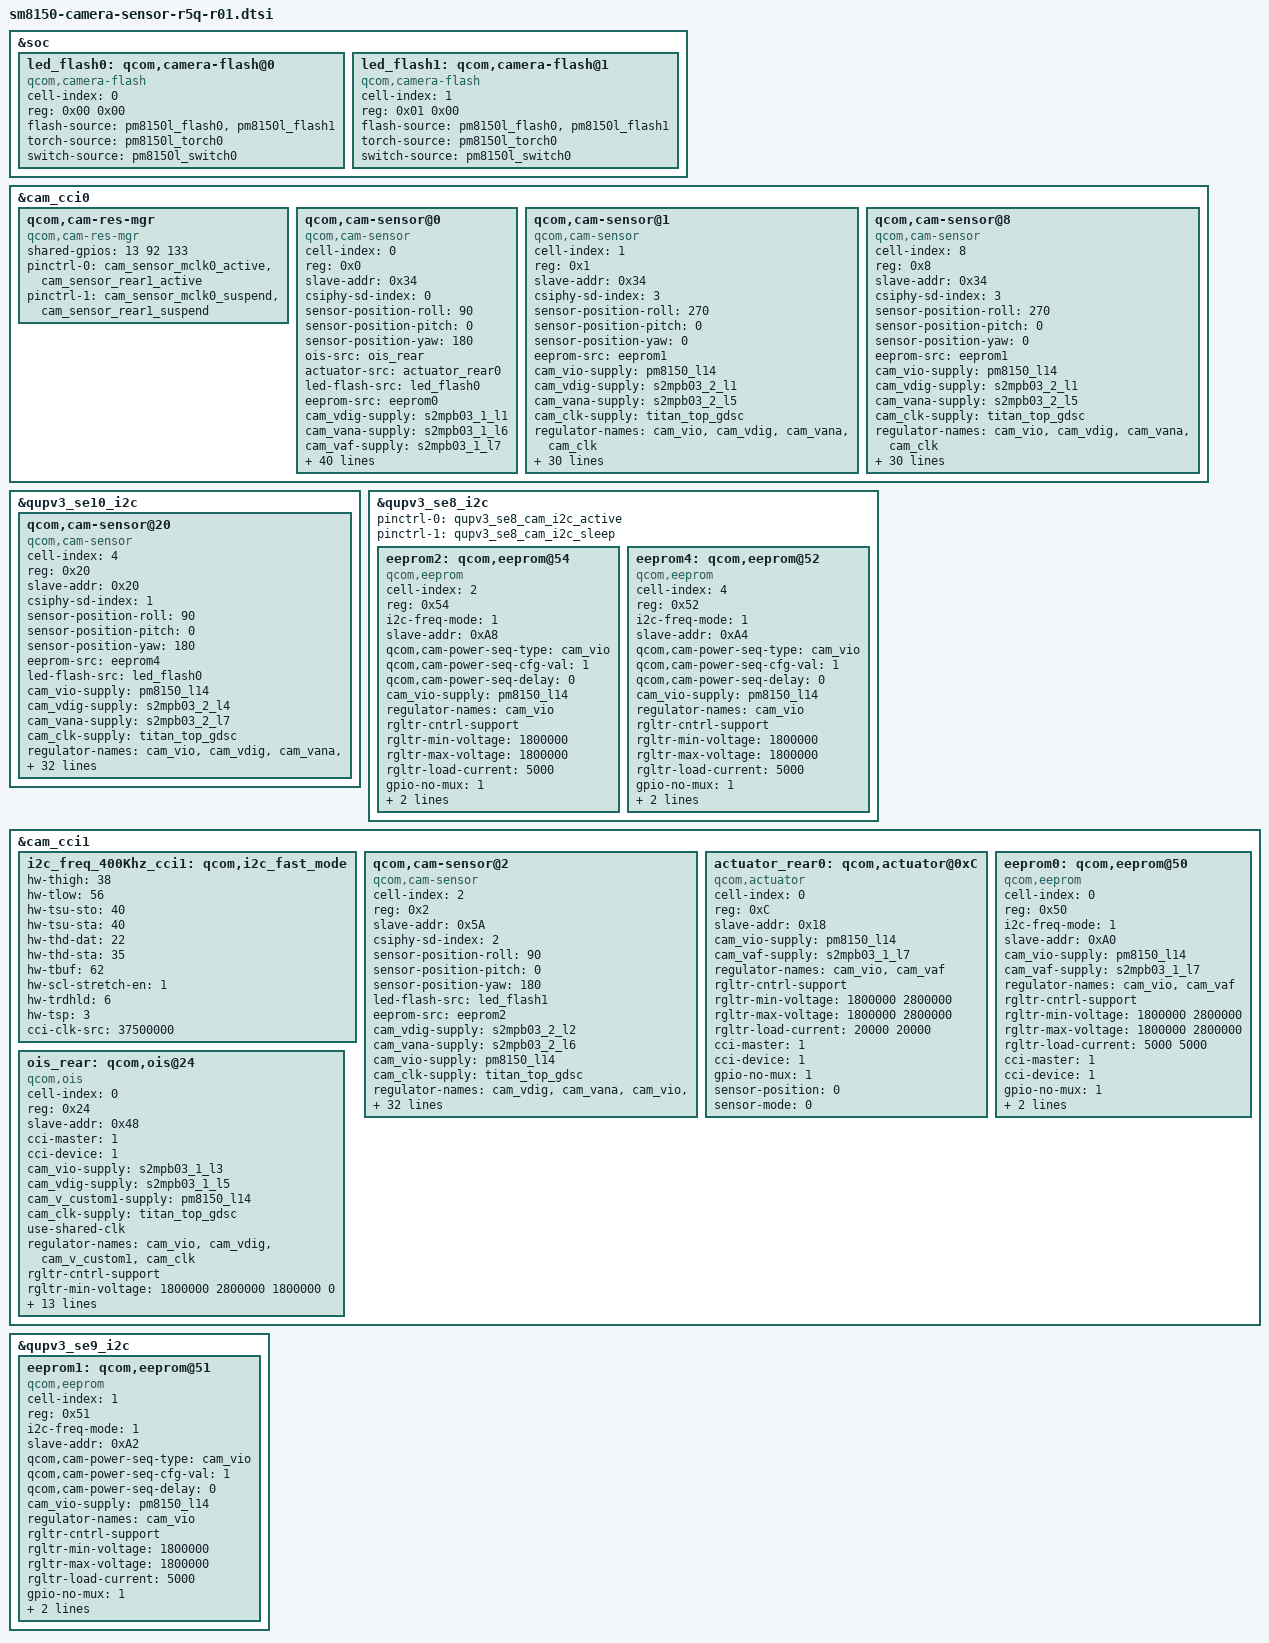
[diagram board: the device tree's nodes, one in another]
&soc {
    led_flash0: qcom,camera-flash@0 {
                cell-index = <0>;
                reg = <0x00 0x00>;
                compatible = "qcom,camera-flash";
                flash-source = <&pm8150l_flash0 &pm8150l_flash1>;
                torch-source = <&pm8150l_torch0>;
                switch-source = <&pm8150l_switch0>;        
                status = "ok";
    };
    
    led_flash1: qcom,camera-flash@1 {
                cell-index = <1>;
                reg = <0x01 0x00>;
                compatible = "qcom,camera-flash";
                flash-source = <&pm8150l_flash0 &pm8150l_flash1>;
                torch-source = <&pm8150l_torch0>;
                switch-source = <&pm8150l_switch0>;        
                status = "ok";
    };
};

&cam_cci0 {

    qcom,cam-res-mgr {
                compatible = "qcom,cam-res-mgr";
                shared-gpios = <13 92 133>;
                pinctrl-names = "cam_res_mgr_default", "cam_res_mgr_suspend";
                status = "ok";
                pinctrl-0 = <&cam_sensor_mclk0_active &cam_sensor_rear1_active>;
                pinctrl-1 = <&cam_sensor_mclk0_suspend &cam_sensor_rear1_suspend>;
    };

    qcom,cam-sensor@0 {
		cell-index = <0>;
		compatible = "qcom,cam-sensor";
		reg = <0x0>;
		slave-addr = <0x34>;
		csiphy-sd-index = <0>;
		sensor-position-roll = <90>;
		sensor-position-pitch = <0>;
		sensor-position-yaw = <180>;
		ois-src = <&ois_rear>;
		actuator-src = <&actuator_rear0>;
		led-flash-src = <&led_flash0>; 
		eeprom-src = <&eeprom0>; 

		// Regulators		
		cam_vdig-supply = <&s2mpb03_1_l1>;        // digital 1.1 S2MPB03X01-6030 VLDO 1 VDD_RCAM1_DVDD_1P1
		cam_vana-supply = <&s2mpb03_1_l6>;        // analog 2.9  S2MPB03X01-6030 VLOD7 VDD_RCAM1_AVDD_2.9V
		cam_vaf-supply = <&s2mpb03_1_l7>;         // S2MPB03X01-6030 LDO6  VDD_RCAM1_AF_2P8
		cam_vio-supply = <&pm8150_l14>;           // VIO 1.8
		cam_v_custom1-supply = <&s2mpb03_2_l3>;   // S2MPB03X01-6031 LDO3  VDD_RCAM1_AVDD_1P8
		cam_v_custom2-supply = <&s2mpb03_1_l3>;	  // S2MPB03X01-6030 LDO3  VDD_RCAM1_OIS_1P8
		cam_v_custom3-supply = <&s2mpb03_1_l5>;   // S2MPB03X01-6030 LDO6  VDD_RCAM1_OIS_VM_2P8
		cam_clk-supply = <&titan_top_gdsc>;                             
		
		
		regulator-names = "cam_vdig", "cam_vana","cam_vaf","cam_vio","cam_v_custom1","cam_v_custom2","cam_v_custom3","cam_clk";
		rgltr-cntrl-support;
		rgltr-min-voltage = <1100000 2900000 2800000 1800000 1800000 1800000 2800000 0 >;
		rgltr-max-voltage = <1100000 2900000 2800000 1800000 1800000 1800000 2800000 0 >;
		rgltr-load-current = <200000 200000 200000 200000 20000 200000 20000 0>;

		// GPIO
		gpio-no-mux = <0>;
		gpios = <&tlmm 13 0>,
			<&tlmm 92 0>,
			<&tlmm 133 0>;  // GPIO 133 for OIS  VDD_RCAM1_OIS_2P8
		gpio-reset = <1>;
		gpio-custom1 = <2>;
		gpio-req-tbl-num = <0 1 2>;
		gpio-req-tbl-flags = <1 0 0>;
		gpio-req-tbl-label = "CAMIF_MCLK0","CAM_RESET0","RCAM1_OIS";

		sensor-mode = <0>;
		cci-master = <0>;
		status = "ok";
		use-shared-clk;
		clocks = <&clock_camcc CAM_CC_MCLK0_CLK>;
		clock-names = "cam_clk";
		clock-cntl-level = "turbo";
		clock-rates = <24000000>;
		cam,isp = <0>;                  // 0 : INT , 1 : EXT , 2 : SOC
		cam,cal_memory = <2>;           // 0 : N , 1 : FROM , 2 : EEPROM , 3 : OTP
		cam,read_version = <0>;         // 0 : SYSFS , 1 : CAMON
		cam,core_voltage = <0>;         // 0 : N , 1 : Y
		cam,upgrade = <0>;              // 0 : N , 1 : SYSFS , 2 : CAMON
		cam,fw_write = <0>;             // 0 : N , 1 : OS , 2 : SD , 3 : ALL
		cam,fw_dump = <0>;              // 0 : N , 1 : Y
		cam,companion_chip = <0>;       // 0 : N , 1 : Y
		cam,ois = <1>;                  // 0 : N , 1 : Y
		cam,dual_open = <0>;            // 0 : N , 1 : Y
		cam,valid = <1>;                // 0 : N , 1 : Y
	};

    qcom,cam-sensor@1 {
		cell-index = <1>;
		compatible = "qcom,cam-sensor";
		reg = <0x1>;
		slave-addr = <0x34>;
		csiphy-sd-index = <3>;
		sensor-position-roll = <270>;
		sensor-position-pitch = <0>;
		sensor-position-yaw = <0>;
		eeprom-src = <&eeprom1>;
		cam_vio-supply = <&pm8150_l14>;
		cam_vdig-supply = <&s2mpb03_2_l1>;
		cam_vana-supply = <&s2mpb03_2_l5>;
		cam_clk-supply = <&titan_top_gdsc>;
		regulator-names = "cam_vio", "cam_vdig", "cam_vana", "cam_clk";
		rgltr-cntrl-support;
		rgltr-min-voltage = <1800000 1050000 2900000 0>;
		rgltr-max-voltage = <1800000 1050000 2900000 0>;
		rgltr-load-current = <200000 200000 200000 0>;
		gpio-no-mux = <0>;
		pinctrl-names = "cam_default", "cam_suspend";
		pinctrl-0 = <&cam_sensor_mclk2_active &cam_sensor_active_front>;
		pinctrl-1 = <&cam_sensor_mclk2_suspend &cam_sensor_suspend_front>;
		gpios = <&tlmm 15 0>, /*VTCAM_MCLK*/
			<&tlmm 82 0>; /*VTCAM_RST*/
		gpio-reset = <1>;
		gpio-req-tbl-num = <0 1>;
		gpio-req-tbl-flags = <1 0>;
		gpio-req-tbl-label = "CAMIF_MCLK2", "CAM_RESET2";

		sensor-mode = <0>;
		cci-master = <1>;
		status = "ok";
		clocks = <&clock_camcc CAM_CC_MCLK2_CLK>;
		clock-names = "cam_clk";
		clock-cntl-level = "turbo";
		clock-rates = <24000000>;

		cam,isp = <0>;                  // 0 : INT , 1 : EXT , 2 : SOC
		cam,cal_memory = <2>;           // 0 : N , 1 : FROM , 2 : EEPROM , 3 : OTP
		cam,read_version = <0>;         // 0 : SYSFS , 1 : CAMON
		cam,core_voltage = <0>;         // 0 : N , 1 : Y
		cam,upgrade = <0>;              // 0 : N , 1 : SYSFS , 2 : CAMON
		cam,fw_write = <0>;             // 0 : N , 1 : OS , 2 : SD , 3 : ALL
		cam,fw_dump = <0>;              // 0 : N , 1 : Y
		cam,companion_chip = <0>;       // 0 : N , 1 : Y
		cam,ois = <0>;                  // 0 : N , 1 : Y
		cam,dual_open = <0>;            // 0 : N , 1 : Y
		cam,valid = <1>;                // 0 : N , 1 : Y
    };	

    qcom,cam-sensor@8 {
		cell-index = <8>;
		compatible = "qcom,cam-sensor";
		reg = <0x8>;
		slave-addr = <0x34>;
		csiphy-sd-index = <3>;
		sensor-position-roll = <270>;
		sensor-position-pitch = <0>;
		sensor-position-yaw = <0>;
		eeprom-src = <&eeprom1>;
		cam_vio-supply = <&pm8150_l14>;
		cam_vdig-supply = <&s2mpb03_2_l1>;
		cam_vana-supply = <&s2mpb03_2_l5>;
		cam_clk-supply = <&titan_top_gdsc>;
		regulator-names = "cam_vio", "cam_vdig", "cam_vana", "cam_clk";
		rgltr-cntrl-support;
		rgltr-min-voltage = <1800000 1050000 2900000 0>;
		rgltr-max-voltage = <1800000 1050000 2900000 0>;
		rgltr-load-current = <200000 200000 200000 0>;
		gpio-no-mux = <0>;
		pinctrl-names = "cam_default", "cam_suspend";
		pinctrl-0 = <&cam_sensor_mclk2_active &cam_sensor_active_front>;
		pinctrl-1 = <&cam_sensor_mclk2_suspend &cam_sensor_suspend_front>;
		gpios = <&tlmm 15 0>, /*VTCAM_MCLK*/
			<&tlmm 82 0>; /*VTCAM_RST*/
		gpio-reset = <1>;
		gpio-req-tbl-num = <0 1>;
		gpio-req-tbl-flags = <1 0>;
		gpio-req-tbl-label = "CAMIF_MCLK2", "CAM_RESET2";

		sensor-mode = <0>;
		cci-master = <1>;
		status = "ok";
		clocks = <&clock_camcc CAM_CC_MCLK2_CLK>;
		clock-names = "cam_clk";
		clock-cntl-level = "turbo";
		clock-rates = <24000000>;

		cam,isp = <0>;                  // 0 : INT , 1 : EXT , 2 : SOC
		cam,cal_memory = <2>;           // 0 : N , 1 : FROM , 2 : EEPROM , 3 : OTP
		cam,read_version = <0>;         // 0 : SYSFS , 1 : CAMON
		cam,core_voltage = <0>;         // 0 : N , 1 : Y
		cam,upgrade = <0>;              // 0 : N , 1 : SYSFS , 2 : CAMON
		cam,fw_write = <0>;             // 0 : N , 1 : OS , 2 : SD , 3 : ALL
		cam,fw_dump = <0>;              // 0 : N , 1 : Y
		cam,companion_chip = <0>;       // 0 : N , 1 : Y
		cam,ois = <0>;                  // 0 : N , 1 : Y
		cam,dual_open = <0>;            // 0 : N , 1 : Y
		cam,valid = <1>;                // 0 : N , 1 : Y
	};
};

&qupv3_se10_i2c {
    status = "ok";
	
	qcom,cam-sensor@20 {  /* REAR CAM 3 - 5M */
		cell-index = <4>;
		compatible = "qcom,cam-sensor";
		reg = <0x20>;
		slave-addr = <0x20>;
		csiphy-sd-index = <1>;
		sensor-position-roll = <90>;
		sensor-position-pitch = <0>;
		sensor-position-yaw = <180>;
                eeprom-src = <&eeprom4>;
                led-flash-src = <&led_flash0>;


		// LDO
		cam_vio-supply = <&pm8150_l14>;
		cam_vdig-supply = <&s2mpb03_2_l4>; 
		cam_vana-supply = <&s2mpb03_2_l7>;
		cam_clk-supply = <&titan_top_gdsc>;
		regulator-names = "cam_vio", "cam_vdig", "cam_vana", "cam_clk";
		rgltr-cntrl-support;
		rgltr-min-voltage = <1800000 1200000 2800000 0>;
		rgltr-max-voltage = <1800000 1200000 2800000 0>;
		rgltr-load-current = <200000 200000 200000 0>;

		// GPIO
		gpio-no-mux = <0>;
		pinctrl-names = "cam_default", "cam_suspend";
		pinctrl-0 = <&cam_sensor_mclk3_active &cam_sensor_active_sw>;
		pinctrl-1 = <&cam_sensor_mclk3_suspend &cam_sensor_suspend_sw>;

		gpios = <&tlmm 16 0>,
			<&tlmm 21 0>;

		gpio-reset = <1>;
		gpio-req-tbl-num = <0 1>;
		gpio-req-tbl-flags = <1 0>;
		gpio-req-tbl-label = "CAMIF_MCLK3", "CAM_RESET3";

		sensor-mode = <0>;
		cci-device = <0>;
		cci-master = <1>;
		status = "ok";
		clocks = <&clock_camcc CAM_CC_MCLK3_CLK>;
		clock-names = "cam_clk";
		clock-cntl-level = "turbo";
		clock-rates = <19200000>;

		cam,isp = <0>;                  // 0 : INT , 1 : EXT , 2 : SOC
		cam,cal_memory = <0>;           // 0 : N , 1 : FROM , 2 : EEPROM , 3 : OTP
		cam,read_version = <0>;         // 0 : SYSFS , 1 : CAMON
		cam,core_voltage = <0>;         // 0 : N , 1 : Y
		cam,upgrade = <0>;              // 0 : N , 1 : SYSFS , 2 : CAMON
		cam,fw_write = <0>;             // 0 : N , 1 : OS , 2 : SD , 3 : ALL
		cam,fw_dump = <0>;              // 0 : N , 1 : Y
		cam,companion_chip = <0>;       // 0 : N , 1 : Y
		cam,ois = <0>;                  // 0 : N , 1 : Y
		cam,dual_open = <0>;            // 0 : N , 1 : Y
		cam,valid = <1>;                // 0 : N , 1 : Y
	};
};

&qupv3_se8_i2c{
	pinctrl-0 = <&qupv3_se8_cam_i2c_active>;
	pinctrl-1 = <&qupv3_se8_cam_i2c_sleep>;
	status = "ok";
	eeprom2: qcom,eeprom@54 {
		cell-index = <2>;
		reg = <0x54>;
		compatible = "qcom,eeprom";
		i2c-freq-mode = <1>;
		slave-addr = <0xA8>;

		//cci-master = <0>;
		//cci-device = <1>;
		qcom,cam-power-seq-type = "cam_vio";
		qcom,cam-power-seq-cfg-val = <1>;
		qcom,cam-power-seq-delay = <0>;
		cam_vio-supply = <&pm8150_l14>; /* VDD_MAINCAM_IO_1P8 */
		regulator-names = "cam_vio";
		rgltr-cntrl-support;
		rgltr-min-voltage = <1800000>;
		rgltr-max-voltage = <1800000>;
		rgltr-load-current = <5000>;
		
		gpio-no-mux = <1>;
		sensor-position = <0>;
		sensor-mode = <0>;
		status = "ok";
	};            

	eeprom4: qcom,eeprom@52 {
		cell-index = <4>;
		reg = <0x52>;
		compatible = "qcom,eeprom";
		i2c-freq-mode = <1>;
		slave-addr = <0xA4>;

		//cci-master = <0>;
		//cci-device = <1>;
		qcom,cam-power-seq-type = "cam_vio";
		qcom,cam-power-seq-cfg-val = <1>;
		qcom,cam-power-seq-delay = <0>;
		cam_vio-supply = <&pm8150_l14>; /* VDD_MAINCAM_IO_1P8 */
		regulator-names = "cam_vio";
		rgltr-cntrl-support;
		rgltr-min-voltage = <1800000>;
		rgltr-max-voltage = <1800000>;
		rgltr-load-current = <5000>;
		
		gpio-no-mux = <1>;
		sensor-position = <0>;
		sensor-mode = <0>;
		status = "ok";
	};
};

&cam_cci1 {

        /* This node is added to enable the "I2C Clock Stretching" for tOIS module */
        i2c_freq_400Khz_cci1: qcom,i2c_fast_mode {
                        hw-thigh = <38>;
                        hw-tlow = <56>;
                        hw-tsu-sto = <40>;
                        hw-tsu-sta = <40>;
                        hw-thd-dat = <22>;
                        hw-thd-sta = <35>;
                        hw-tbuf = <62>;
                        hw-scl-stretch-en = <1>;
                        hw-trdhld = <6>;
                        hw-tsp = <3>;
                        cci-clk-src = <37500000>;
                        status = "ok";
        };

	qcom,cam-sensor@2 {
		cell-index = <2>;
		compatible = "qcom,cam-sensor";
		reg = <0x2>;
		slave-addr = <0x5A>; 
		csiphy-sd-index = <2>;
		sensor-position-roll = <90>;
		sensor-position-pitch = <0>;
		sensor-position-yaw = <180>;
		/*actuator-src = <&actuator_rear0>;*/
		led-flash-src = <&led_flash1>; 
		eeprom-src = <&eeprom2>; 

		// Regulators	
		cam_vdig-supply = <&s2mpb03_2_l2>;        // analog 1.05  S2MPB03X01-6030 VLOD2 VDD_RCAM3_DVDD_1P05V        
		cam_vana-supply = <&s2mpb03_2_l6>;        // digital 2.8 S2MPB03X01-6030 VLDO6 VDD_RCAM3_AVDD_2P8V
	        cam_vio-supply = <&pm8150_l14>;         // PMIC vio	
		cam_clk-supply = <&titan_top_gdsc>;                 
		
		
		regulator-names = "cam_vdig", "cam_vana","cam_vio","cam_clk";
		rgltr-cntrl-support;
		rgltr-min-voltage = <1050000 2800000 1800000 0 >;
		rgltr-max-voltage = <1050000 2800000 1800000 0 >;
		rgltr-load-current = <200000 200000 200000 0>;

		// GPIO
		gpio-no-mux = <0>;
		pinctrl-names = "cam_default", "cam_suspend";
		pinctrl-0 = <&cam_sensor_mclk1_active &cam_sensor_rear2_active>;
		pinctrl-1 = <&cam_sensor_mclk1_suspend &cam_sensor_rear2_suspend>;
		gpios = <&tlmm 14 0>,//UWCAM_MCLK
			<&tlmm 22 0>; //UWCAM_RST_N  
		gpio-reset = <1>;
		gpio-req-tbl-num = <0 1>;
		gpio-req-tbl-flags = <1 0>;
		gpio-req-tbl-label = "CAMIF_MCLK1","CAM_RESET1"; 

		sensor-mode = <0>;
		cci-master = <0>;
		cci-device = <1>;
		status = "ok";
		clocks = <&clock_camcc CAM_CC_MCLK1_CLK>;
		clock-names = "cam_clk";
		clock-cntl-level = "turbo";
		clock-rates = <19200000>;
		cam,isp = <0>;                  // 0 : INT , 1 : EXT , 2 : SOC
		cam,cal_memory = <2>;           // 0 : N , 1 : FROM , 2 : EEPROM , 3 : OTP
		cam,read_version = <0>;         // 0 : SYSFS , 1 : CAMON
		cam,core_voltage = <0>;         // 0 : N , 1 : Y
		cam,upgrade = <0>;              // 0 : N , 1 : SYSFS , 2 : CAMON
		cam,fw_write = <0>;             // 0 : N , 1 : OS , 2 : SD , 3 : ALL
		cam,fw_dump = <0>;              // 0 : N , 1 : Y
		cam,companion_chip = <0>;       // 0 : N , 1 : Y
		cam,ois = <0>;                  // 0 : N , 1 : Y
		cam,dual_open = <0>;            // 0 : N , 1 : Y
		cam,valid = <1>;                // 0 : N , 1 : Y
	};
	
	actuator_rear0: qcom,actuator@0xC {
		cell-index = <0>;
		reg = <0xC>;
		compatible = "qcom,actuator";
		slave-addr = <0x18>;


		cam_vio-supply = <&pm8150_l14>;
		cam_vaf-supply = <&s2mpb03_1_l7>;

                regulator-names = "cam_vio","cam_vaf";
		rgltr-cntrl-support;
		rgltr-min-voltage = <1800000 2800000>;
		rgltr-max-voltage = <1800000 2800000>;
		rgltr-load-current = <20000 20000>;

		cci-master = <1>;
		cci-device = <1>;   

		gpio-no-mux = <1>;
		sensor-position = <0>;
		sensor-mode = <0>;
		status = "ok";
	};       
	eeprom0: qcom,eeprom@50 {
		cell-index = <0>;
		reg = <0x50>;
		compatible = "qcom,eeprom";
		i2c-freq-mode = <1>;
		slave-addr = <0xA0>;
                
		cam_vio-supply = <&pm8150_l14>; /* VDD_MAINCAM_IO_1P8 */ 
		cam_vaf-supply = <&s2mpb03_1_l7>;
        
		regulator-names = "cam_vio","cam_vaf";
		rgltr-cntrl-support;
		rgltr-min-voltage = <1800000 2800000>;
		rgltr-max-voltage = <1800000 2800000>;
		rgltr-load-current = <5000 5000>;
		
		cci-master = <1>;
		cci-device = <1>;     
		
		gpio-no-mux = <1>;
		sensor-position = <0>;
		sensor-mode = <0>;
		status = "ok";
	};

	ois_rear: qcom,ois@24  {   /* IMX586 RUMBA_S4 tOIS module */
		compatible = "qcom,ois";
		cell-index = <0>;
		reg = <0x24>;
                slave-addr = <0x48>;
		cci-master = <1>;
		cci-device = <1>;
		cam_vio-supply = <&s2mpb03_1_l3>;	// S2MPB03X01-6030 LDO3 VDD_RCAM1_OIS_1P8
                cam_vdig-supply = <&s2mpb03_1_l5>;      // S2MPB03X01-6030 LDO6 VDD_RCAM1_OIS_VM_2P8
		cam_v_custom1-supply = <&pm8150_l14>;   // VIO supply
                cam_clk-supply = <&titan_top_gdsc>;
                use-shared-clk;

		regulator-names = "cam_vio", "cam_vdig","cam_v_custom1","cam_clk";
		rgltr-cntrl-support;
		rgltr-min-voltage = <1800000 2800000 1800000 0>;
		rgltr-max-voltage = <1800000 2800000 1800000 0>;
		rgltr-load-current = <5000 5000 5000 0>;
		gpio-no-mux = <0>;

                gpios = <&tlmm 13 0>,
			<&tlmm 92 0>,
                        <&tlmm 133 0>;  // GPIO 133 for OIS  VDD_RCAM1_OIS_2P8
                gpio-reset = <1>;
                gpio-custom1 = <2>;
                gpio-req-tbl-num = <0 1 2>;
                gpio-req-tbl-flags = <1 0 0>;
                gpio-req-tbl-label = "CAMIF_MCLK0","CAM_RESET0","RCAM1_OIS";

                clocks = <&clock_camcc CAM_CC_MCLK0_CLK>;
                clock-names = "cam_clk";
                clock-cntl-level = "turbo";
                clock-rates = <24000000>;
	
		status = "ok";
	};	
};

&qupv3_se9_i2c{
        status = "ok";
        eeprom1: qcom,eeprom@51 {
                cell-index = <1>;
                reg = <0x51>;
                compatible = "qcom,eeprom";
                i2c-freq-mode = <1>;
                slave-addr = <0xA2>;

                //cci-master = <1>;
                //cci-device = <1>;
                qcom,cam-power-seq-type = "cam_vio";
                qcom,cam-power-seq-cfg-val = <1>;
                qcom,cam-power-seq-delay = <0>;
                cam_vio-supply = <&pm8150_l14>; /* VDD_MAINCAM_IO_1P8 */
                regulator-names = "cam_vio";
                rgltr-cntrl-support;
                rgltr-min-voltage = <1800000>;
                rgltr-max-voltage = <1800000>;
                rgltr-load-current = <5000>;
		
                gpio-no-mux = <1>;
                sensor-position = <0>;
                sensor-mode = <0>;
                status = "ok";
        };
};

